# CY8C5868AXI_LP035 register map
File version: 0.1
Registers are 8-bit, read-write, no defined reset value unless marked. A register's access mark holds for its fields unless they carry their own. Offsets are from the block's base; [hi:lo] are bit positions; {n}, {i} and the like mark numbered series; 'fields as' and 'values as' point back to an identical list.

## Detect_Seuil_Recept
Base 0x00000000
0x400043A7 Detect_Seuil_Recept_Comp_PM_ACT_CFG — Active Power Mode Configuration Register 7
  [3:0] en_cmp — Enable comparator. Populated subsystems are counted from the LSB, for example bit 0 corresponds to comparator 0
0x400043B7 Detect_Seuil_Recept_Comp_PM_STBY_CFG — Standby Power Mode Configuration Register 7
  fields as Detect_Seuil_Recept_Comp_PM_ACT_CFG
0x40004630 Detect_Seuil_Recept_Comp_TR0 — Comparator Trim Register_TR0
  [4:0] trimA_4_0_ — Sets the trim value to be added to the P-type load for offset calibration
    0=TRIMA_0 (Does not add any offset); {v}=TRIMA_POS_SIDE_{v} (Adds offset of ~{v}mV to the positive side) (v=1..8); {v}=TRIMA_NEG_SIDE_{v-9} (Adds offset of ~{v-10}mV to the negative side) (v=10..18)
0x40004631 Detect_Seuil_Recept_Comp_TR1 — Comparator Trim Register_TR1
  [4:0] trimB_4_0_ — Sets the trim value to be added to the N-type load for offset calibration
    0=TRIMB_0 (Does not add any offset); {v}=TRIMB_NEG_SIDE_{v} (Adds offset of ~{v}mV to the negative side) (v=1..8); 10=TRIMB_9 (Does not add any offset); {v}=TRIMB_POS_SIDE_{v-10} (Adds offset of ~{v-10}mV to the positive side) (v=11..18)
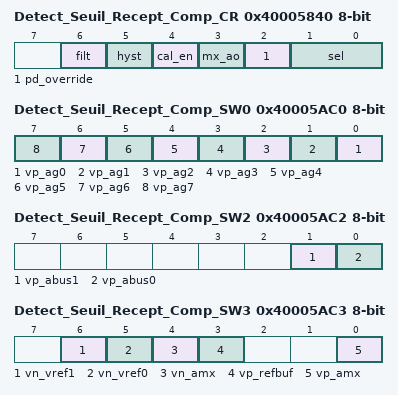
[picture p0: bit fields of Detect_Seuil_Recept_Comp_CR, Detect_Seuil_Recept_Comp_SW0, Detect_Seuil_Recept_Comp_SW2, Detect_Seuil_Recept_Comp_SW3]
0x40005840 Detect_Seuil_Recept_Comp_CR — Comparator Control Register
  [6] filt — enables a glitch filter at the output of the comparator
    0=FILT_DISABLE (Disable glitch filter); 1=FILT_ENABLE (Enable glitch filter)
  [5] hyst — enables a hysteresis of 10mV typ
    1=HYST_DISABLE (Disable hysteresis); 0=HYST_ENABLE (Enable hysteresis)
  [4] cal_en — enables shorting of the two comparator inputs for trim calibration purposes
    0=CAL_EN_DISABLE (Disable calibration); 1=CAL_EN_ENABLE (Enable calibration)
  [3] mx_ao — comparator sleep always-on logic mux control
    0=MX_AO_BYPASS (Bypass comparator sleep always-on logic); 1=MX_AO_ENABLE (Enable comparator sleep always-on logic)
  [2] pd_override — Power down override to allow comparator to continue operating during sleep
    0=PD_OVERRIDE_DISABLE (Don't override power down); 1=PD_OVERRIDE_ENABLE (Override power down)
  [1:0] sel — Selects the mode of operation of the comparator
    0=SEL_SLOW (slow mode); 1=SEL_FAST (fast mode); 2=SEL_LP (ultra low power mode); 3=SEL_ILLEGAL (Illegal Mode)
0x40005AC0 Detect_Seuil_Recept_Comp_SW0 — Comparator Analog Routing Register 0
  [all] fields
    0=AG_NC (not connected); 1=AG_CONNECTED (Connect to Analog Global)
  [n] vp_ag{n} (n=0..7) — Connect positive voltage input to analog global of same side
0x40005AC2 Detect_Seuil_Recept_Comp_SW2 — Comparator Analog Routing Register 2
  [1] vp_abus1 — Connect positive voltage input to analog (local) bus of the same side
    0=ABUS_NC (not connected); 1=ABUS_CONNECTED (Connect to Analog (local) Bus)
  [0] vp_abus0 — Connect positive voltage input to analog (local) bus of the same side
    values as vp_abus1
0x40005AC3 Detect_Seuil_Recept_Comp_SW3 — Comparator Analog Routing Register 3
  [6] vn_vref1 — Connect negative voltage input to Voltage Reference 1
    0=VREF_NC (not connected); 1=VREF_CONNECTED (Connect to Voltage Reference)
  [5] vn_vref0 — Connect negative voltage input to Voltage Reference 0
    values as vn_vref1
  [4] vn_amx — Connect negative voltage input to Analog Mux Bus
    0=AMX_NC (not connected); 1=AMX_CONNECTED (Connect to AMUXBUS)
  [3] vp_refbuf — Connect positive voltage input to CapSense reference buffer channel
    0=VP_REFBUF_ENABLED (disable); 1=VP_REFBUF_DISABLED (enable)
  [0] vp_amx — Connect positive voltage input to Analog Mux Bus
    values as vn_amx
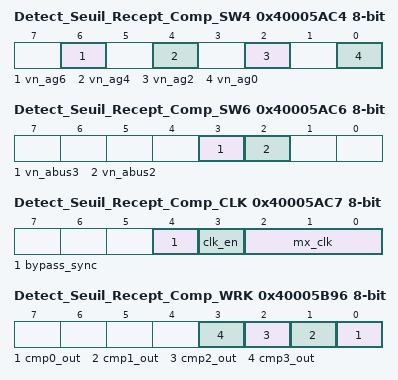
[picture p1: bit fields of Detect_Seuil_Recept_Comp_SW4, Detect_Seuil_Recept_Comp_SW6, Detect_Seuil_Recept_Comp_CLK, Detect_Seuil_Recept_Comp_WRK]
0x40005AC4 Detect_Seuil_Recept_Comp_SW4 — Comparator Analog Routing Register 4
  [all] fields
    values as the fields of Detect_Seuil_Recept_Comp_SW0
  [6] vn_ag6 — Connect negative voltage input to analog global of same side
  [4] vn_ag4 — Connect negative voltage input to analog global of same side
  [2] vn_ag2 — Connect negative voltage input to analog global of same side
  [0] vn_ag0 — Connect negative voltage input to analog global of same side
0x40005AC6 Detect_Seuil_Recept_Comp_SW6 — Comparator Analog Routing Register 6
  [3] vn_abus3 — Connect negative voltage input to analog (local) bus of the same side
    values as Detect_Seuil_Recept_Comp_SW2.vp_abus1
  [2] vn_abus2 — Connect negative voltage input to analog (local) bus of the same side
    values as Detect_Seuil_Recept_Comp_SW2.vp_abus1
0x40005AC7 Detect_Seuil_Recept_Comp_CLK — Comparator Clock Control Register
  [4] bypass_sync — Bypass Synchronization
    0=Synchronization not bypassed (Synchronization enabled); 1=Synchronization bypassed (Synchronization disabled)
  [3] clk_en — Clock gating control
    0=disable clock; 1=enable clock
  [2:0] mx_clk — Clock Selection
    {v}=Select clk_a{v} and clk_a{v}_dig (v=0..3); 4=Select UDB generated clock
0x40005B96 Detect_Seuil_Recept_Comp_WRK — Comparator output working register
  [n] cmp{n}_out ro (n=0..3) — Comparator Output

## V_seuil
Base 0x00000000
0x400043A8 VDAC8_PM_ACT_CFG — Active Power Mode Configuration Register 8
  [4:0] en_dac — Enable DAC block(s). Populated subsystems are counted from the LSB
0x400043B8 VDAC8_PM_STBY_CFG — Standby Power Mode Configuration Register 8
  fields as VDAC8_PM_ACT_CFG
0x4000460A VDAC8_TR
  [7:0] tr — 8 Calibration bits
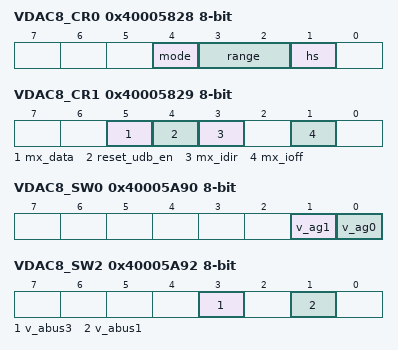
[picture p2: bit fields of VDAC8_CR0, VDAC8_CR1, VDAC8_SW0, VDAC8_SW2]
0x40005828 VDAC8_CR0 — DAC Block Control Register 0
  [4] mode ro — Mode Bit
    0=DAC_MODE_V (voltage DAC); 1=DAC_MODE_I (current DAC)
  [3:2] range — Ranges for mode=0 (VDAC) and mode=1 (IDAC)
    0=DAC_RANGE_0 (x0=0V to 4*vref (1.024V); 0 to 31.875uA); 1=DAC_RANGE_1 (x1=0V to 16*vref (4.096V); 0 to 255uA); 2=DAC_RANGE_2 (x0=0V to 4*vref (1.024V); 0 to 2.040mA); 3=DAC_RANGE_3 (x1=0V to 16*vref (4.096V); not used)
  [1] hs — High Speed Bit
    0=DAC_HS_LOWPOWER (regular (low power)); 1=DAC_HS_HIGHSPEED (high speed (higher power))
0x40005829 VDAC8_CR1 — DAC Block Control Register 1
  [5] mx_data — Select DATA source
    0=MX_DATA_REG (Select register source (DACxn_D)); 1=MX_DATA_UDB (Select UDB source)
  [4] reset_udb_en — DAC reset enable
    0=RESET_UDB_EN_DISABLE (Disable DAC Reset Source from UDB (System reset always resets)); 1=RESET_UDB_EN_ENABLE (Enable DAC Reset Source from UDB)
  [3] mx_idir — Mux selection for DAC current direction control
    0=MX_IDIR_REG (Register source idirbit selected); 1=MX_IDIR_UDB (UDB ictrl selected)
  [1] mx_ioff — Mux selection for DAC current off control
    0=MX_IOFF_REG (Register source ioffbit selected); 1=MX_IOFF_UDB (UDB ictrl selected)
0x40005A90 VDAC8_SW0 — DAC Analog Routing Register 0
  [1] v_ag1 — Connect voltage output to analog global of same side
    0=AG_NC (not connected); 1=AG_CONNECTED (Connect to Analog Global)
  [0] v_ag0 — Connect voltage output to analog global of same side
    values as v_ag1
0x40005A92 VDAC8_SW2 — DAC Analog Routing Register 2
  [3] v_abus3 — Connect voltage output to analog (local) bus of the same side
    0=ABUS_NC (not connected); 1=ABUS_CONNECTED (Connect to Analog (local) Bus)
  [1] v_abus1 — Connect voltage output to analog (local) bus of the same side
    values as v_abus3
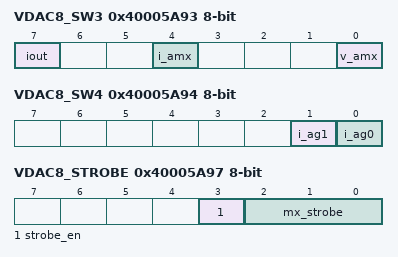
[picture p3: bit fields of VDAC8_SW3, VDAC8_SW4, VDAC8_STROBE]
0x40005A93 VDAC8_SW3 — DAC Analog Routing Register 3
  [7] iout — Connect current output to pad
    0=IOUT_NC (not connected); 1=IOUT_CONNECT (Connect to pad)
  [4] i_amx — Connect current output to Analog Mux Bus
    0=AMX_NC (not connected); 1=AMX_CONNECTED (Connect to AMUXBUS)
  [0] v_amx — Connect voltage output to Analog Mux Bus
    values as i_amx
0x40005A94 VDAC8_SW4 — DAC Analog Routing Register 4
  [1] i_ag1 — Connect current output to analog global of same side
    values as VDAC8_SW0.v_ag1
  [0] i_ag0 — Connect current output to analog global of same side
    values as VDAC8_SW0.v_ag1
0x40005A97 VDAC8_STROBE — DAC Strobe Register
  [3] strobe_en — Strobe gating control (See mx_strobe==3'h0)
    0=disable strobe; 1=enable strobe
  [2:0] mx_strobe — Strobe source selection
    0=MX_STROBE_BUSWRITE (Select bus write strobe source (Enable gater regardless of strobe_en setting)); 1=MX_STROBE_UDB_SRC (Select UDB strobe source); 2=MX_STROBE_NC_2 (NC); 3=MX_STROBE_NC_3 (NC); {v}=MX_STROBE_CLK_A{v-4}_DIG (Select clk_a{v-4}_dig) (v=4..7)
0x40005B82 VDAC8_DATA — DAC Data Register
  [7:0] data — 8 DAC Data bits
